# apollo3p register map
Vendor: Ambiq Micro; Series: Apollo; File version: 1.0
CPU: CM4 r1p0, little endian, MPU, FPU, I-cache, D-cache, VTOR, ITCM, DTCM, 3 interrupt priority bits, 0 interrupts
Registers are 32-bit, read-write, reset 0x0 unless marked. A register's access mark holds for its fields unless they carry their own. Offsets are from the block's base; [hi:lo] are bit positions.

## UART0 — Serial UART
Base 0x4001C000
Same registers: UART1 0x4001D000
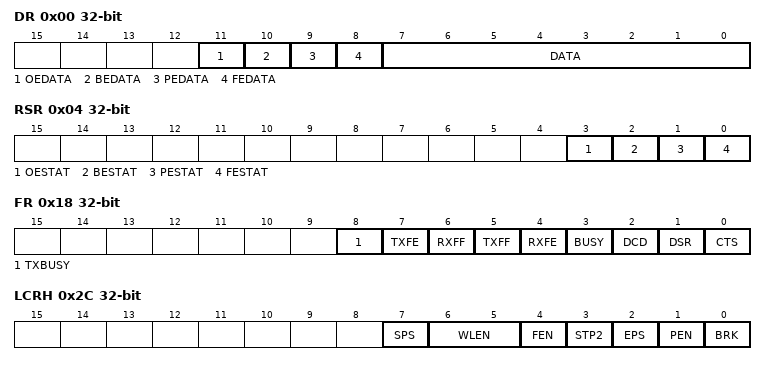
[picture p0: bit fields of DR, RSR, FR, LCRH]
0x00 DR — UART Data
  [11] OEDATA — This is the overrun error indicator.
    0=NOERR (No error on UART OEDATA, overrun error indicator.); 1=ERR (Error on UART OEDATA, overrun error indicator.)
  [10] BEDATA — This is the break error indicator.
    0=NOERR (No error on UART BEDATA, break error indicator.); 1=ERR (Error on UART BEDATA, break error indicator.)
  [9] PEDATA — This is the parity error indicator.
    0=NOERR (No error on UART PEDATA, parity error indicator.); 1=ERR (Error on UART PEDATA, parity error indicator.)
  [8] FEDATA — This is the framing error indicator.
    0=NOERR (No error on UART FEDATA, framing error indicator.); 1=ERR (Error on UART FEDATA, framing error indicator.)
  [7:0] DATA — This is the UART data port.
0x04 RSR — UART Status
  [3] OESTAT — This is the overrun error indicator.
    0=NOERR (No error on UART OESTAT, overrun error indicator.); 1=ERR (Error on UART OESTAT, overrun error indicator.)
  [2] BESTAT — This is the break error indicator.
    0=NOERR (No error on UART BESTAT, break error indicator.); 1=ERR (Error on UART BESTAT, break error indicator.)
  [1] PESTAT — This is the parity error indicator.
    0=NOERR (No error on UART PESTAT, parity error indicator.); 1=ERR (Error on UART PESTAT, parity error indicator.)
  [0] FESTAT — This is the framing error indicator.
    0=NOERR (No error on UART FESTAT, framing error indicator.); 1=ERR (Error on UART FESTAT, framing error indicator.)
0x18 FR — Flag
  [8] TXBUSY — This bit holds the transmit BUSY indicator.
  [7] TXFE — This bit holds the transmit FIFO empty indicator.
    1=XMTFIFO_EMPTY (Transmit FIFO is empty.)
  [6] RXFF — This bit holds the receive FIFO full indicator.
    1=RCVFIFO_FULL (Receive FIFO is full.)
  [5] TXFF — This bit holds the transmit FIFO full indicator.
    1=XMTFIFO_FULL (Transmit FIFO is full.)
  [4] RXFE — This bit holds the receive FIFO empty indicator.
    1=RCVFIFO_EMPTY (Receive FIFO is empty.)
  [3] BUSY — This bit holds the busy indicator.
    1=BUSY (UART busy indicator.)
  [2] DCD — This bit holds the data carrier detect indicator.
    1=DETECTED (Data carrier detect detected.)
  [1] DSR — This bit holds the data set ready indicator.
    1=READY (Data set ready.)
  [0] CTS — This bit holds the clear to send indicator.
    1=CLEARTOSEND (Clear to send is indicated.)
0x20 ILPR — IrDA Counter
  [7:0] ILPDVSR — These bits hold the IrDA counter divisor.
0x24 IBRD — Integer Baud Rate Divisor
  [15:0] DIVINT — These bits hold the baud integer divisor.
0x28 FBRD — Fractional Baud Rate Divisor
  [5:0] DIVFRAC — These bits hold the baud fractional divisor.
0x2C LCRH — Line Control High
  [7] SPS — This bit holds the stick parity select.
  [6:5] WLEN — These bits hold the write length.
  [4] FEN — This bit holds the FIFO enable.
  [3] STP2 — This bit holds the two stop bits select.
  [2] EPS — This bit holds the even parity select.
  [1] PEN — This bit holds the parity enable.
  [0] BRK — This bit holds the break set.
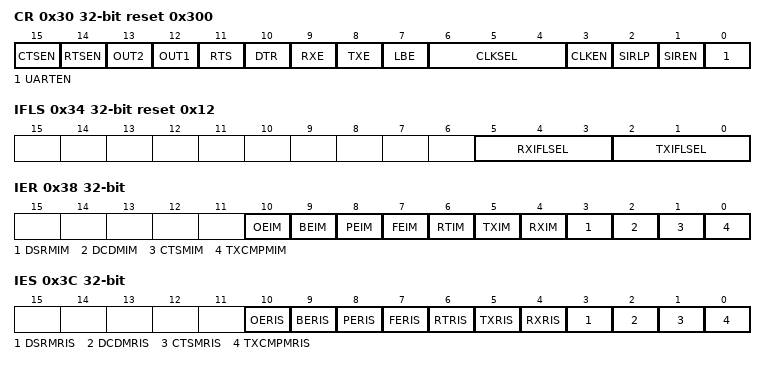
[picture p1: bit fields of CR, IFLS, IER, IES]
0x30 CR reset 0x300 — Control
  [15] CTSEN — This bit enables CTS hardware flow control.
  [14] RTSEN — This bit enables RTS hardware flow control.
  [13] OUT2 — This bit holds modem Out2.
  [12] OUT1 — This bit holds modem Out1.
  [11] RTS — This bit enables request to send.
  [10] DTR — This bit enables data transmit ready.
  [9] RXE — This bit is the receive enable.
  [8] TXE — This bit is the transmit enable.
  [7] LBE — This bit is the loopback enable.
  [6:4] CLKSEL — This bit field is the UART clock select.
    0=NOCLK (No UART clock. This is the low power default.); 1=24MHZ (24 MHz clock.); 2=12MHZ (12 MHz clock.); 3=6MHZ (6 MHz clock.); 4=3MHZ (3 MHz clock.)
  [3] CLKEN — This bit is the UART clock enable.
  [2] SIRLP — This bit is the SIR low power select.
  [1] SIREN — This bit is the SIR ENDEC enable.
  [0] UARTEN — This bit is the UART enable.
0x34 IFLS reset 0x12 — FIFO Interrupt Level Select
  [5:3] RXIFLSEL — These bits hold the receive FIFO interrupt level.
  [2:0] TXIFLSEL — These bits hold the transmit FIFO interrupt level.
0x38 IER — Interrupt Enable
  [10] OEIM — This bit holds the overflow interrupt enable.
  [9] BEIM — This bit holds the break error interrupt enable.
  [8] PEIM — This bit holds the parity error interrupt enable.
  [7] FEIM — This bit holds the framing error interrupt enable.
  [6] RTIM — This bit holds the receive timeout interrupt enable.
  [5] TXIM — This bit holds the transmit interrupt enable.
  [4] RXIM — This bit holds the receive interrupt enable.
  [3] DSRMIM — This bit holds the modem DSR interrupt enable.
  [2] DCDMIM — This bit holds the modem DCD interrupt enable.
  [1] CTSMIM — This bit holds the modem CTS interrupt enable.
  [0] TXCMPMIM — This bit holds the modem TXCMP interrupt enable.
0x3C IES — Interrupt Status
  [10] OERIS — This bit holds the overflow interrupt status.
  [9] BERIS — This bit holds the break error interrupt status.
  [8] PERIS — This bit holds the parity error interrupt status.
  [7] FERIS — This bit holds the framing error interrupt status.
  [6] RTRIS — This bit holds the receive timeout interrupt status.
  [5] TXRIS — This bit holds the transmit interrupt status.
  [4] RXRIS — This bit holds the receive interrupt status.
  [3] DSRMRIS — This bit holds the modem DSR interrupt status.
  [2] DCDMRIS — This bit holds the modem DCD interrupt status.
  [1] CTSMRIS — This bit holds the modem CTS interrupt status.
  [0] TXCMPMRIS — This bit holds the modem TXCMP interrupt status.
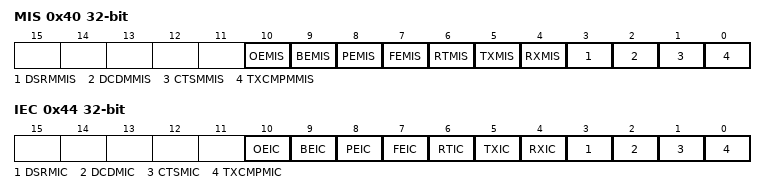
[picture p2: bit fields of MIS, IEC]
0x40 MIS — Masked Interrupt Status
  [10] OEMIS — This bit holds the overflow interrupt status masked.
  [9] BEMIS — This bit holds the break error interrupt status masked.
  [8] PEMIS — This bit holds the parity error interrupt status masked.
  [7] FEMIS — This bit holds the framing error interrupt status masked.
  [6] RTMIS — This bit holds the receive timeout interrupt status masked.
  [5] TXMIS — This bit holds the transmit interrupt status masked.
  [4] RXMIS — This bit holds the receive interrupt status masked.
  [3] DSRMMIS — This bit holds the modem DSR interrupt status masked.
  [2] DCDMMIS — This bit holds the modem DCD interrupt status masked.
  [1] CTSMMIS — This bit holds the modem CTS interrupt status masked.
  [0] TXCMPMMIS — This bit holds the modem TXCMP interrupt status masked.
0x44 IEC — Interrupt Clear
  [10] OEIC — This bit holds the overflow interrupt clear.
  [9] BEIC — This bit holds the break error interrupt clear.
  [8] PEIC — This bit holds the parity error interrupt clear.
  [7] FEIC — This bit holds the framing error interrupt clear.
  [6] RTIC — This bit holds the receive timeout interrupt clear.
  [5] TXIC — This bit holds the transmit interrupt clear.
  [4] RXIC — This bit holds the receive interrupt clear.
  [3] DSRMIC — This bit holds the modem DSR interrupt clear.
  [2] DCDMIC — This bit holds the modem DCD interrupt clear.
  [1] CTSMIC — This bit holds the modem CTS interrupt clear.
  [0] TXCMPMIC — This bit holds the modem TXCMP interrupt clear.
